# CC13x0 register map
File version: 2.0
CPU: CM3 r2p1, little endian, no MPU, no FPU, 0x3 interrupt priority bits, 0x0 interrupts
Registers are 32-bit, read-write, reset 0x0 unless marked. A register's access mark holds for its fields unless they carry their own. Offsets are from the block's base; [hi:lo] are bit positions; {n}, {i} and the like mark numbered series.

## GPT0 — General Purpose Timer.
Base 0x40010000
Same registers: GPT1 0x40011000, GPT2 0x40012000, GPT3 0x40013000
0x00 CFG — Configuration
  [2:0] CFG
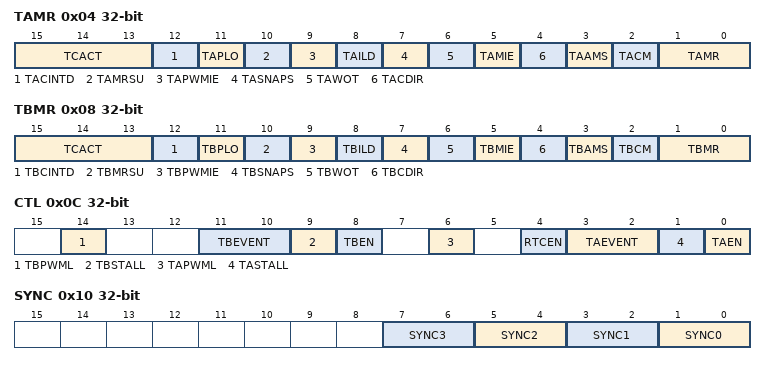
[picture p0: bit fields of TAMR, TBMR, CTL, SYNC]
0x04 TAMR — Timer A Mode
  [15:13] TCACT, [12] TACINTD, [11] TAPLO, [10] TAMRSU, [9] TAPWMIE, [8] TAILD, [7] TASNAPS, [6] TAWOT, [5] TAMIE, [4] TACDIR, [3] TAAMS, [2] TACM, [1:0] TAMR
0x08 TBMR — Timer B Mode
  [15:13] TCACT, [12] TBCINTD, [11] TBPLO, [10] TBMRSU, [9] TBPWMIE, [8] TBILD, [7] TBSNAPS, [6] TBWOT, [5] TBMIE, [4] TBCDIR, [3] TBAMS, [2] TBCM, [1:0] TBMR
0x0C CTL — Control
  [14] TBPWML, [11:10] TBEVENT, [9] TBSTALL, [8] TBEN, [6] TAPWML, [4] RTCEN, [3:2] TAEVENT, [1] TASTALL, [0] TAEN
0x10 SYNC — Synch Register
  [2n+1:2n] SYNC{n} (n=0..3)
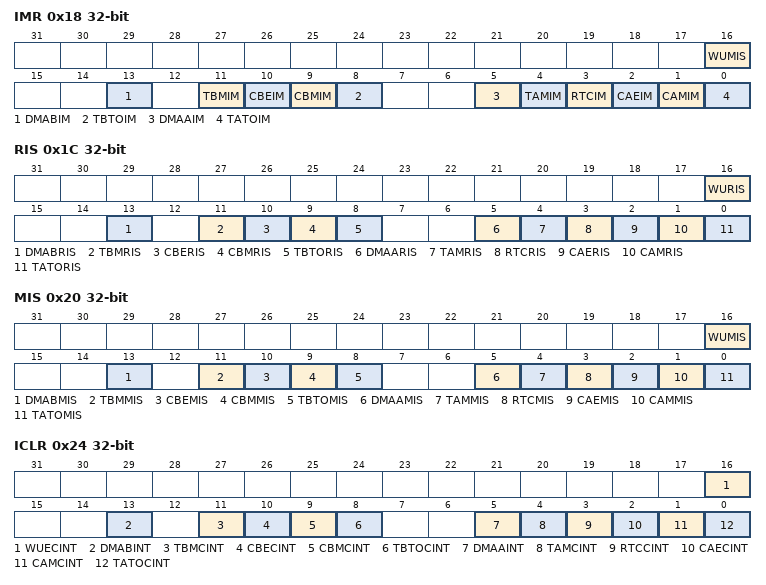
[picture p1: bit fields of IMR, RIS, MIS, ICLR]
0x18 IMR — Interrupt Mask This register is used to enable the interrupts. Associated registers: RIS, MIS, ICLR
  [16] WUMIS, [13] DMABIM, [11] TBMIM, [10] CBEIM, [9] CBMIM, [8] TBTOIM, [5] DMAAIM, [4] TAMIM, [3] RTCIM, [2] CAEIM, [1] CAMIM, [0] TATOIM
0x1C RIS ro — Raw Interrupt Status Associated registers: IMR, MIS, ICLR
  [16] WURIS, [13] DMABRIS, [11] TBMRIS, [10] CBERIS, [9] CBMRIS, [8] TBTORIS, [5] DMAARIS, [4] TAMRIS, [3] RTCRIS, [2] CAERIS, [1] CAMRIS, [0] TATORIS
0x20 MIS ro — Masked Interrupt Status Values are result of bitwise AND operation between RIS and IMR Assosciated clear register: ICLR
  [16] WUMIS, [13] DMABMIS, [11] TBMMIS, [10] CBEMIS, [9] CBMMIS, [8] TBTOMIS, [5] DMAAMIS, [4] TAMMIS, [3] RTCMIS, [2] CAEMIS, [1] CAMMIS, [0] TATOMIS
0x24 ICLR — Interrupt Clear This register is used to clear status bits in the RIS and MIS registers
  [16] WUECINT write-1-clears, [13] DMABINT write-1-clears, [11] TBMCINT write-1-clears, [10] CBECINT write-1-clears, [9] CBMCINT write-1-clears, [8] TBTOCINT write-1-clears, [5] DMAAINT write-1-clears, [4] TAMCINT write-1-clears, [3] RTCCINT write-1-clears, [2] CAECINT write-1-clears, [1] CAMCINT write-1-clears, [0] TATOCINT write-1-clears
0x28 TAILR reset 0xFFFFFFFF — Timer A Interval Load Register
0x2C TBILR reset 0xFFFF — Timer B Interval Load Register
0x30 TAMATCHR reset 0xFFFFFFFF — Timer A Match Register Interrupts can be generated when the timer value is equal to the value in this register in one-shot or periodic mode. In Edge-Count mode, this register along with TAILR, determines how many edge events are counted. The total number of edge events counted is equal to the value in TAILR minus this value. Note that in edge-count mode, when executing an up-count, the value of TAPR and TAILR must be greater than the value of TAPMR and TAMATCHR. In PWM mode, this value along with TAILR, determines the duty cycle of the output PWM signal. When a 16/32-bit GPT is configured to one of the 32-bit modes, TAMATCHR appears as a 32-bit register. (The upper 16-bits correspond to the contents TBMATCHR). In a 16-bit mode, the upper 16 bits of this register read as 0s and have no effect on the state of TBMATCHR. Note : This register is updated internally (takes effect) based on TAMR.TAMRSU
0x34 TBMATCHR reset 0xFFFF — Timer B Match Register When a GPT is configured to one of the 32-bit modes, the contents of bits 15:0 in this register are loaded into the upper 16 bits of TAMATCHR. Reads from this register return the current match value of Timer B and writes are ignored. In a 16-bit mode, bits 15:0 are used for the match value. Bits 31:16 are reserved in both cases. Note : This register is updated internally (takes effect) based on TBMR.TBMRSU
  [15:0] TBMATCHR
0x38 TAPR — Timer A Pre-scale This register allows software to extend the range of the timers when they are used individually. When in one-shot or periodic down count modes, this register acts as a true prescaler for the timer counter. When acting as a true prescaler, the prescaler counts down to 0 before the value in TAR and TAV registers are incremented. In all other individual/split modes, this register is a linear extension of the upper range of the timer counter, holding bits 23:16 in the 16-bit modes of the 16/32-bit GPT.
  [7:0] TAPSR
0x3C TBPR — Timer B Pre-scale This register allows software to extend the range of the timers when they are used individually. When in one-shot or periodic down count modes, this register acts as a true prescaler for the timer counter. When acting as a true prescaler, the prescaler counts down to 0 before the value in TBR and TBV registers are incremented. In all other individual/split modes, this register is a linear extension of the upper range of the timer counter, holding bits 23:16 in the 16-bit modes of the 16/32-bit GPT.
  [7:0] TBPSR
0x40 TAPMR — Timer A Pre-scale Match This register allows software to extend the range of the TAMATCHR when used individually.
  [7:0] TAPSMR
0x44 TBPMR — Timer B Pre-scale Match This register allows software to extend the range of the TBMATCHR when used individually.
  [7:0] TBPSMR
0x48 TAR ro reset 0xFFFFFFFF — Timer A Register
0x4C TBR ro reset 0xFFFF — Timer B Register
0x50 TAV reset 0xFFFFFFFF — Timer A Value This register shows the current value of the free running 16-bit Timer A. In the 32-bit mode
0x54 TBV reset 0xFFFF — Timer B Value This register shows the current value of the free running 16-bit Timer B. Note: When the alternate timer clock (TIMCLK) is enabled, a read of a timer value will return the current count 1.
0x58 RTCPD ro reset 0x7FFF — RTC Pre-divide Value This register shows the current value of the RTC pre-divider in RTC mode. Note: When the alternate timer clock (TIMCLK) is enabled, a read of a timer value will return the current count -1.
  [15:0] RTCPD
0x5C TAPS ro — Timer A Pre-scale Snap-shot Based on the value in the register field TAMR.TAILD, this register is updated with the value from TAPR register either on the next cycle or on the next timeout. This register shows the current value of the Timer A pre-scaler in the 16-bit mode. Note: When the alternate timer clock (TIMCLK) is enabled a read of a timer value will return the current count -1.
  [7:0] PSS
0x60 TBPS ro — Timer B Pre-scale Snap-shot Based on the value in the register field TBMR.TBILD, this register is updated with the value from TBPR register either on the next cycle or on the next timeout. This register shows the current value of the Timer B pre-scaler in the 16-bit mode. Note: When the alternate timer clock (TIMCLK) is enabled a read of a timer value will return the current count -1.
  [7:0] PSS
0x64 TAPV ro — Timer A Pre-scale Value This register shows the current value of the Timer A free running pre-scaler in the 16-bit mode. Note: When the alternate timer clock (TIMCLK) is enabled, a read of a timer value will return the current count 1.
  [7:0] PSV
0x68 TBPV ro — Timer B Pre-scale Value This register shows the current value of the Timer B free running pre-scaler in the 16-bit mode. Note: When the alternate timer clock (TIMCLK) is enabled, a read of a timer value will return the current count-1.
  [7:0] PSV
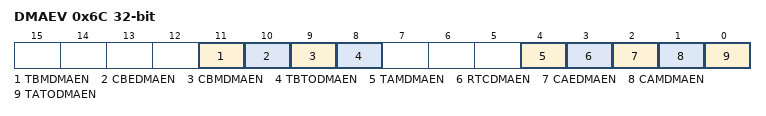
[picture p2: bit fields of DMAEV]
0x6C DMAEV — DMA Event This register allows software to enable/disable GPT DMA trigger events.
  [11] TBMDMAEN, [10] CBEDMAEN, [9] CBMDMAEN, [8] TBTODMAEN, [4] TAMDMAEN, [3] RTCDMAEN, [2] CAEDMAEN, [1] CAMDMAEN, [0] TATODMAEN
0xFB0 VERSION ro reset 0x400 — Peripheral Version This register provides information regarding the GPT version
0xFB4 ANDCCP — Combined CCP Output This register is used to logically AND CCP output pairs for each timer
  [0] CCP_AND_EN
